VERSION "1.0"

NS_ :

BS_:

BU_: BMS VCU TESTER

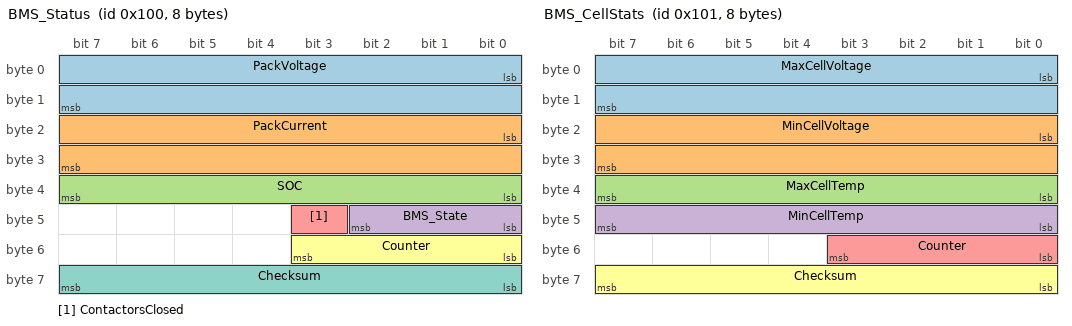
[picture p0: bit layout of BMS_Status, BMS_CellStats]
BO_ 256 BMS_Status: 8 BMS
 SG_ PackVoltage : 0|16@1+ (0.01,0) [0|655.35] "V" VCU
 SG_ PackCurrent : 16|16@1- (0.1,0) [-3276.8|3276.7] "A" VCU
 SG_ SOC : 32|8@1+ (0.5,0) [0|100] "%" VCU
 SG_ BMS_State : 40|3@1+ (1,0) [0|4] "" VCU
 SG_ ContactorsClosed : 43|1@1+ (1,0) [0|1] "" VCU
 SG_ Counter : 48|4@1+ (1,0) [0|15] "" VCU
 SG_ Checksum : 56|8@1+ (1,0) [0|255] "" VCU

BO_ 257 BMS_CellStats: 8 BMS
 SG_ MaxCellVoltage : 0|16@1+ (0.001,0) [0|65.535] "V" VCU
 SG_ MinCellVoltage : 16|16@1+ (0.001,0) [0|65.535] "V" VCU
 SG_ MaxCellTemp : 32|8@1+ (1,-40) [-40|215] "degC" VCU
 SG_ MinCellTemp : 40|8@1+ (1,-40) [-40|215] "degC" VCU
 SG_ Counter : 48|4@1+ (1,0) [0|15] "" VCU
 SG_ Checksum : 56|8@1+ (1,0) [0|255] "" VCU

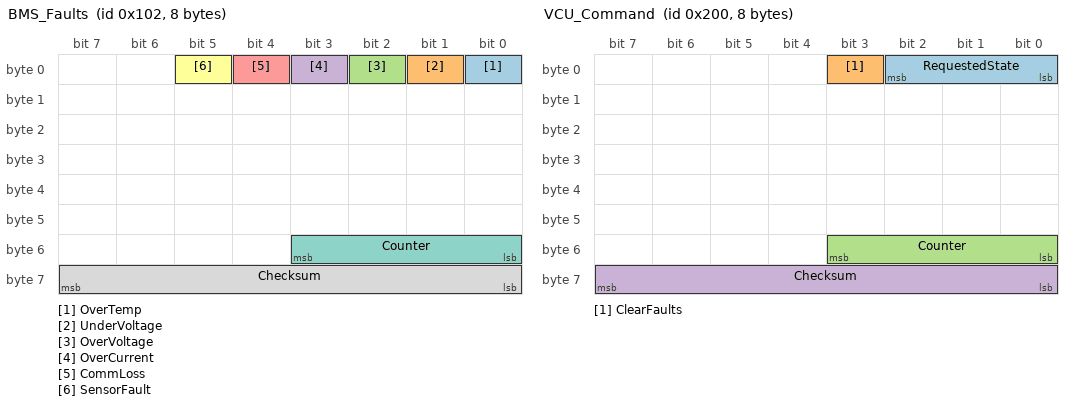
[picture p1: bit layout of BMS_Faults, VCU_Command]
BO_ 258 BMS_Faults: 8 BMS
 SG_ OverTemp : 0|1@1+ (1,0) [0|1] "" VCU
 SG_ UnderVoltage : 1|1@1+ (1,0) [0|1] "" VCU
 SG_ OverVoltage : 2|1@1+ (1,0) [0|1] "" VCU
 SG_ OverCurrent : 3|1@1+ (1,0) [0|1] "" VCU
 SG_ CommLoss : 4|1@1+ (1,0) [0|1] "" VCU
 SG_ SensorFault : 5|1@1+ (1,0) [0|1] "" VCU
 SG_ Counter : 48|4@1+ (1,0) [0|15] "" VCU
 SG_ Checksum : 56|8@1+ (1,0) [0|255] "" VCU

BO_ 512 VCU_Command: 8 VCU
 SG_ RequestedState : 0|3@1+ (1,0) [0|4] "" BMS
 SG_ ClearFaults : 3|1@1+ (1,0) [0|1] "" BMS
 SG_ Counter : 48|4@1+ (1,0) [0|15] "" BMS
 SG_ Checksum : 56|8@1+ (1,0) [0|255] "" BMS

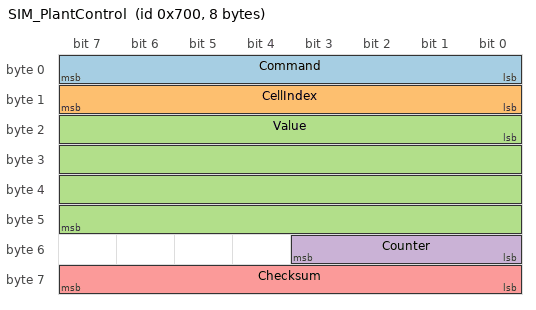
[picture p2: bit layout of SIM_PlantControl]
BO_ 1792 SIM_PlantControl: 8 TESTER
 SG_ Command : 0|8@1+ (1,0) [0|255] "" BMS
 SG_ CellIndex : 8|8@1+ (1,0) [0|255] "" BMS
 SG_ Value : 16|32@1- (0.001,0) [-2147483.648|2147483.647] "" BMS
 SG_ Counter : 48|4@1+ (1,0) [0|15] "" BMS
 SG_ Checksum : 56|8@1+ (1,0) [0|255] "" BMS

CM_ BO_ 256 "Pack-level status, 100 ms cycle.";
CM_ BO_ 257 "Cell extremes, 100 ms cycle.";
CM_ BO_ 258 "Latched fault flags, 100 ms cycle.";
CM_ BO_ 512 "Vehicle controller heartbeat and state request, 50 ms cycle.";
CM_ BO_ 1792 "Test-harness control of the simulated battery plant (load, sensor fault injection, reset). Not present on a production bus.";
CM_ SG_ 1792 Value "Load current in A, temperature in degC or voltage in V depending on Command.";

VAL_ 256 BMS_State 0 "INIT" 1 "STANDBY" 2 "DRIVE" 3 "CHARGE" 4 "FAULT" ;
VAL_ 512 RequestedState 0 "NONE" 1 "STANDBY" 2 "DRIVE" 3 "CHARGE" ;
VAL_ 1792 Command 0 "NOP" 1 "SET_LOAD_CURRENT" 2 "SET_CELL_TEMP" 3 "SET_CELL_VOLTAGE" 4 "OPEN_TEMP_SENSOR" 5 "CLEAR_INJECTIONS" 6 "RESET" ;
